AUTOSAR XML (schema 4-3-0)
standard types defined: boolean, sint16, sint8, uint16, uint8
package /AUTOSAR_AISpecification/PhysicalDimensions
  physical dimension Distance: length-exp=1  # No Dimension
  physical dimension TiNeg1: time-exp=-1  # Time -1
package /AUTOSAR_AISpecification/Units
  unit NoUnit: display-name=-, factor-si-to-unit=1, physical-dimension=Distance  # No Unit | Unit for dimensionless continuous value data types like numbers, factors and coefficients
  unit RadPerSec: display-name=rad/s, factor-si-to-unit=1, physical-dimension=TiNeg1  # Radian per Second | SI derived unit of angular velocity
package /Communication/Clusters
  can cluster CanBodyCluster: baudrate=500000, protocol-name=CAN, protocol-version=2.0B
    can physical channel CanBodyPhysicalChannel: comm-connectors=[Gateway_BodyCanConnector, BCM_BodyConnector]
      frame GeneralInfoCanFrame: id 0x5, from CentralGatewayEcu, to BodyControlEcu, frame-length=1, can-addressing-mode=EXTENDED, can-frame-rx-behavior=CAN-20, can-frame-tx-behavior=CAN-20  # CanFrame for ISignalIPdu FuelRateEngineIPdu
        pdu GeneralInfoIPdu: length=1, minimum-delay=0, transmission-mode-condition{data-filter=data-filter-type=ALWAYS, i-signal-in-i-pdu=Kl_15_ISignalToPduMapping}, transmission-mode-true-timing=cyclic-timing={time-offset=0, time-period=0.01}, unused-bit-pattern=0
          signal Kl_15ISignal: start 0, 1 bit, little-endian, init-value=0, base-type=boolean, data-constr=DC_Boolean, transfer-property=PENDING, to BodyControlEcu EngineEcu GearBoxEcu  # ISignal for SystemSignal  # Simple Status Flag
      frame DoorLeftStatusCanFrame: id 0x1, from BodyControlEcu, to CentralGatewayEcu, frame-length=2, can-addressing-mode=EXTENDED, can-frame-rx-behavior=CAN-20, can-frame-tx-behavior=CAN-20  # CanFrame for ISignalIPdu FuelRateEngineIPdu
        pdu DoorLeftStatusCanIPdu: length=2, minimum-delay=0, transmission-mode-condition{data-filter=data-filter-type=ALWAYS, i-signal-in-i-pdu=DoorLeftStatusCanIPdu/DoorClosedLeftSignal}, transmission-mode-true-timing=cyclic-timing={time-offset=0, time-period=0.01}, unused-bit-pattern=0
          signal DoorLeftClosedISignal: start 0, 1 bit, little-endian, system signal DoorClosed, init-value=0, base-type=boolean, compu-method=OpenClosed, data-constr=DC_Boolean, transfer-property=PENDING, to CentralGatewayEcu BodyControlEcu  # ISignal for SystemSignal  # Simple Status Flag
          signal DoorLeftLockedISignal: start 8, 1 bit, little-endian, system signal DoorLocked, init-value=0, base-type=boolean, compu-method=OpenClosed, data-constr=DC_Boolean, transfer-property=PENDING, to CentralGatewayEcu BodyControlEcu  # ISignal for SystemSignal  # Simple Status Flag
      frame DoorRightStatusCanFrame: id 0x2, from BodyControlEcu, to CentralGatewayEcu, frame-length=2, can-addressing-mode=EXTENDED, can-frame-rx-behavior=CAN-20, can-frame-tx-behavior=CAN-20  # CanFrame for ISignalIPdu FuelRateEngineIPdu
        pdu DoorRightStatusCanIPdu: length=2, minimum-delay=0, transmission-mode-condition{data-filter=data-filter-type=ALWAYS, i-signal-in-i-pdu=DoorRightStatusCanIPdu/DoorClosedRightSignal}, transmission-mode-true-timing=cyclic-timing={time-offset=0, time-period=0.01}, unused-bit-pattern=0
          signal DoorRightClosedISignal: start 0, 1 bit, little-endian, system signal DoorClosed, init-value=0, base-type=boolean, data-constr=DC_Boolean, transfer-property=PENDING, to CentralGatewayEcu BodyControlEcu  # ISignal for SystemSignal  # Simple Status Flag
          signal DoorRightLockedISignal: start 8, 1 bit, little-endian, system signal DoorLocked, init-value=0, base-type=boolean, compu-method=OpenClosed, data-constr=DC_Boolean, transfer-property=PENDING, to CentralGatewayEcu BodyControlEcu  # ISignal for SystemSignal  # Simple Status Flag
      frame CarLockControlCanFrame: id 0x3, from BodyControlEcu, to CentralGatewayEcu, frame-length=2, can-addressing-mode=EXTENDED, can-frame-rx-behavior=CAN-20, can-frame-tx-behavior=CAN-20  # CanFrame for ISignalIPdu FuelRateEngineIPdu
        pdu CarLockControlIPdu: length=2, minimum-delay=0, transmission-mode-condition{data-filter=data-filter-type=ALWAYS, i-signal-in-i-pdu=LockCarSignal}, transmission-mode-true-timing=cyclic-timing={time-offset=0, time-period=0.1}, unused-bit-pattern=0
          signal LockCarISignal: start 0, 1 bit, little-endian, base-type=boolean, data-constr=DC_Boolean, transfer-property=PENDING, to CentralGatewayEcu DoorEcuLeft DoorEcuRight  # ISignal for SystemSignal  # Simple Status Flag
          signal UnlockCarISignal: start 8, 1 bit, little-endian, base-type=boolean, data-constr=DC_Boolean, transfer-property=PENDING, to CentralGatewayEcu DoorEcuLeft DoorEcuRight  # ISignal for SystemSignal  # Simple Status Flag
      frame GearBoxInfoFrame: id 0x4, from CentralGatewayEcu, to BodyControlEcu, frame-length=3, can-addressing-mode=EXTENDED, can-frame-rx-behavior=CAN-20, can-frame-tx-behavior=CAN-20  # CanFrame for ISignalIPdu FuelRateEngineIPdu
        pdu GearBoxInfoIPdu: length=3, minimum-delay=0, transmission-mode-condition{data-filter=data-filter-type=ALWAYS, i-signal-in-i-pdu=CurrentGearToPduMapping}, transmission-mode-true-timing=cyclic-timing={time-offset=0, time-period=0.01}, unused-bit-pattern=0
          signal CurrentGearISignal: start 0, 8 bit, little-endian, system signal GearInfo, init-value=0, base-type=uint8, range phys -1..7, transfer-property=PENDING, to BodyControlEcu CentralGatewayEcu EngineEcu  # ISignal for SystemSignal
          signal SpeedISignal: start 8, 8 bit, little-endian, base-type=uint8, data-constr=DC_Speed, transfer-property=PENDING, to BodyControlEcu CentralGatewayEcu EngineEcu  # ISignal for SystemSignal Speed  # Engine speed before sensor failure correction
  can cluster CanPowertrainCluster: baudrate=500000, protocol-name=CAN, protocol-version=2.0B  # High speed CAN cluster for communication between ECU Controller and ECU EngineModel.
    can physical channel CanPowertrainPhysicalChannel: comm-connectors=[Engine_PowertrainCanConnector, GearBox_PowertrainCanConnector, Gateway_PowertrainCanConnector]  # High speed CAN channel.
      frame PowerStatusFrame: id 0xB, from CentralGatewayEcu, to EngineEcu GearBoxEcu, frame-length=1, can-addressing-mode=EXTENDED, can-frame-rx-behavior=CAN-20, can-frame-tx-behavior=CAN-20  # CanFrame for ISignalIPdu FuelRateEngineIPdu
        pdu PowerStatusIPdu: length=1, minimum-delay=0, transmission-mode-condition{data-filter=data-filter-type=ALWAYS, i-signal-in-i-pdu=Kl_15ISignal}, transmission-mode-true-timing=cyclic-timing={time-offset=0, time-period=0.01}, unused-bit-pattern=0
          signal Kl_15ISignal: start 0, 1 bit, little-endian, init-value=0, base-type=boolean, data-constr=DC_Boolean, transfer-property=PENDING, to BodyControlEcu EngineEcu GearBoxEcu  # ISignal for SystemSignal  # Simple Status Flag
      frame GearBoxInfoFrame: id 0xC, from GearBoxEcu, to EngineEcu CentralGatewayEcu, frame-length=3, can-addressing-mode=EXTENDED, can-frame-rx-behavior=CAN-20, can-frame-tx-behavior=CAN-20  # CanFrame for ISignalIPdu FuelRateEngineIPdu
        carries pdu GearBoxInfoIPdu: packing-byte-order=little-endian, start-position=0
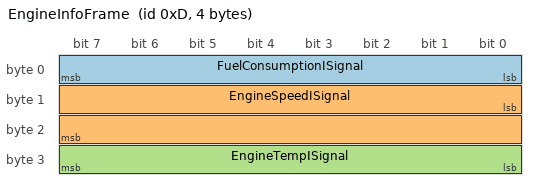
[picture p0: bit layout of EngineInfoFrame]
      frame EngineInfoFrame: id 0xD, from EngineEcu, to CentralGatewayEcu, frame-length=4, can-addressing-mode=STANDARD, can-frame-rx-behavior=CAN-20, can-frame-tx-behavior=CAN-20  # CanFrame for ISignalIPdu EngineInfoFrameIPdu
        pdu EngineInfoIPdu: length=4, minimum-delay=0, transmission-mode-condition{data-filter=data-filter-type=ALWAYS, i-signal-in-i-pdu=FuelConsumptionToPduMapping}, transmission-mode-true-timing=cyclic-timing={time-offset=0, time-period=0.1}, unused-bit-pattern=0
          signal FuelConsumptionISignal: start 0, 8 bit, little-endian, base-type=uint8, range phys 0..100 "Data constraint for current fuel consumption", transfer-property=PENDING, to CentralGatewayEcu  # ISignal for SystemSignal FuelConsumption  # Current Fuel Consumption
          signal EngineSpeedISignal: start 8, 16 bit, little-endian, base-type=sint16, range phys 0..1000 "Data constraint for current fuel consumption", implementation-data-type=uint16, transfer-property=PENDING, to CentralGatewayEcu  # ISignal for SystemSignal RoundsPerMinute  # Engine speed in rounds per minute of crankshaft
          signal EngineTempISignal: start 24, 8 bit, little-endian, base-type=sint8, range phys 0..200 "Data constraint for current fuel consumption", transfer-property=PENDING, to CentralGatewayEcu  # ISignal for SystemSignal EngineTemp  # Temperature of the engine
  lin cluster LinDoorCluster: baudrate=19200, protocol-name=LIN, protocol-version=2.1  # LIN cluster for communication between ECU BodyControllModule, ECU DoorLeft and ECU DoorRight.
    lin physical channel LinDoorPhysicalChannel: comm-connectors=[BCM_DoorConnector, LinDoorLeftConnector, LinDoorRightConnector]  # LIN physical channel.
      frame DoorLeftStatusLinFrame: id 0x1, from DoorEcuLeft, to BodyControlEcu, frame-length=2, lin-checksum=ENHANCED
        pdu DoorLeftStatusIPdu: length=2, minimum-delay=0, transmission-mode-condition{data-filter=data-filter-type=ALWAYS, i-signal-in-i-pdu=DoorLeftStatusIPdu/DoorClosedLeftSignal}, transmission-mode-true-timing=cyclic-timing={time-offset=0, time-period=0.01}, unused-bit-pattern=0
          signal DoorLeftClosedISignal: start 0, 1 bit, little-endian, system signal DoorClosed, init-value=0, base-type=boolean, compu-method=OpenClosed, data-constr=DC_Boolean, transfer-property=PENDING, to CentralGatewayEcu BodyControlEcu  # ISignal for SystemSignal  # Simple Status Flag
          signal DoorLeftLockedISignal: start 8, 1 bit, little-endian, system signal DoorLocked, init-value=0, base-type=boolean, compu-method=OpenClosed, data-constr=DC_Boolean, transfer-property=PENDING, to CentralGatewayEcu BodyControlEcu  # ISignal for SystemSignal  # Simple Status Flag
      frame DoorRightStatusLinFrame: id 0x2, from DoorEcuRight, to BodyControlEcu, frame-length=2, lin-checksum=ENHANCED
        pdu DoorRightStatusIPdu: length=2, minimum-delay=0, transmission-mode-condition{data-filter=data-filter-type=ALWAYS, i-signal-in-i-pdu=DoorRightStatusIPdu/DoorClosedRightSignal}, transmission-mode-true-timing=cyclic-timing={time-offset=0, time-period=0.01}, unused-bit-pattern=0
          signal DoorRightClosedISignal: start 0, 1 bit, little-endian, system signal DoorClosed, init-value=0, base-type=boolean, data-constr=DC_Boolean, transfer-property=PENDING, to CentralGatewayEcu BodyControlEcu  # ISignal for SystemSignal  # Simple Status Flag
          signal DoorRightLockedISignal: start 8, 1 bit, little-endian, system signal DoorLocked, init-value=0, base-type=boolean, compu-method=OpenClosed, data-constr=DC_Boolean, transfer-property=PENDING, to CentralGatewayEcu BodyControlEcu  # ISignal for SystemSignal  # Simple Status Flag
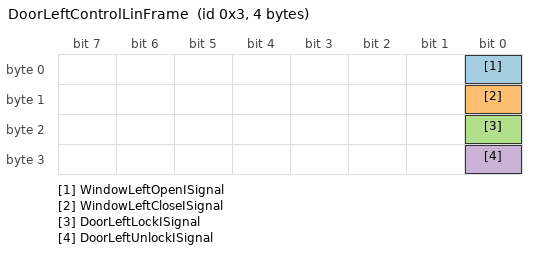
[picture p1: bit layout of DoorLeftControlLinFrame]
      frame DoorLeftControlLinFrame: id 0x3, from BodyControlEcu, to DoorEcuLeft, frame-length=4, lin-checksum=ENHANCED
        pdu DoorLeftControlIPdu: length=4, minimum-delay=0, transmission-mode-true-timing=cyclic-timing={time-offset=0, time-period=0.01}, unused-bit-pattern=0
          transmission-mode-conditions:
            data-filter=data-filter-type=ALWAYS, i-signal-in-i-pdu=CloseWindowLeftSignal
            data-filter=data-filter-type=ALWAYS, i-signal-in-i-pdu=LockDoorLeftSignal
            data-filter=data-filter-type=ALWAYS, i-signal-in-i-pdu=OpenWindowLeftSignal
            data-filter=data-filter-type=ALWAYS, i-signal-in-i-pdu=UnlockDoorLeftSignal
          signal WindowLeftOpenISignal: start 0, 1 bit, little-endian, system signal OpenWindow, base-type=boolean, data-constr=DC_Boolean, transfer-property=PENDING, to DoorEcuLeft  # ISignal for SystemSignal  # Simple Status Flag
          signal WindowLeftCloseISignal: start 8, 1 bit, little-endian, system signal CloseWindow, base-type=boolean, data-constr=DC_Boolean, transfer-property=PENDING, to DoorEcuLeft  # ISignal for SystemSignal  # Simple Status Flag
          signal DoorLeftLockISignal: start 16, 1 bit, little-endian, system signal LockDoor, base-type=boolean, transfer-property=PENDING  # ISignal for SystemSignal  # Simple Status Flag
          signal DoorLeftUnlockISignal: start 24, 1 bit, little-endian, system signal UnlockDoor, base-type=boolean, transfer-property=PENDING  # ISignal for SystemSignal  # Simple Status Flag
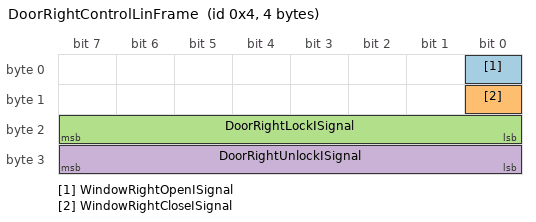
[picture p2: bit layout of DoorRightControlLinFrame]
      frame DoorRightControlLinFrame: id 0x4, from BodyControlEcu, to DoorEcuRight, frame-length=4, lin-checksum=ENHANCED
        pdu DoorRightControlIPdu: length=4, minimum-delay=0, transmission-mode-true-timing=cyclic-timing={time-offset=0, time-period=0.01}, unused-bit-pattern=0
          transmission-mode-conditions:
            data-filter=data-filter-type=ALWAYS, i-signal-in-i-pdu=DoorRightControlIPdu/CloseWindowRightSignal
            data-filter=data-filter-type=ALWAYS, i-signal-in-i-pdu=DoorRightControlIPdu/LockDoorRightSignal
            data-filter=data-filter-type=ALWAYS, i-signal-in-i-pdu=DoorRightControlIPdu/OpenWindowRightSignal
            data-filter=data-filter-type=ALWAYS, i-signal-in-i-pdu=DoorRightControlIPdu/UnlockDoorRightSignal
          signal WindowRightOpenISignal: start 0, 1 bit, little-endian, system signal OpenWindow, base-type=boolean, data-constr=DC_Boolean, transfer-property=PENDING, to DoorEcuRight  # ISignal for SystemSignal  # Simple Status Flag
          signal WindowRightCloseISignal: start 8, 1 bit, little-endian, system signal CloseWindow, base-type=boolean, data-constr=DC_Boolean, transfer-property=PENDING, to DoorEcuRight  # ISignal for SystemSignal  # Simple Status Flag
          signal DoorRightLockISignal: start 16, 8 bit, little-endian, system signal LockDoor, base-type=boolean, transfer-property=PENDING  # ISignal for SystemSignal  # Simple Status Flag
          signal DoorRightUnlockISignal: start 24, 8 bit, little-endian, system signal UnlockDoor, base-type=boolean, transfer-property=PENDING  # ISignal for SystemSignal  # Simple Status Flag
      frame CarLockControlLinFrame: id 0x5, from BodyControlEcu, to DoorEcuLeft DoorEcuRight, frame-length=2, lin-checksum=ENHANCED
        carries pdu CarLockControlIPdu: packing-byte-order=little-endian, start-position=0
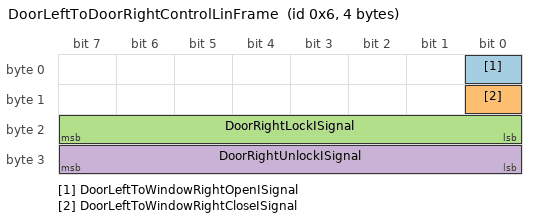
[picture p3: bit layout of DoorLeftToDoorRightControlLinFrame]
      frame DoorLeftToDoorRightControlLinFrame: id 0x6, from DoorEcuLeft, to DoorEcuRight, frame-length=4
        pdu DoorLeftToDoorRightControlIPdu: length=4, minimum-delay=0, transmission-mode-true-timing=cyclic-timing={time-offset=0, time-period=0.01}, unused-bit-pattern=0
          transmission-mode-conditions:
            data-filter=data-filter-type=ALWAYS, i-signal-in-i-pdu=DoorLeftToDoorRightControlIPdu/CloseWindowRightSignal
            data-filter=data-filter-type=ALWAYS, i-signal-in-i-pdu=DoorLeftToDoorRightControlIPdu/LockDoorRightSignal
            data-filter=data-filter-type=ALWAYS, i-signal-in-i-pdu=DoorLeftToDoorRightControlIPdu/OpenWindowRightSignal
            data-filter=data-filter-type=ALWAYS, i-signal-in-i-pdu=DoorLeftToDoorRightControlIPdu/UnlockDoorRightSignal
          signal DoorLeftToWindowRightOpenISignal: start 0, 1 bit, little-endian, system signal OpenWindow, base-type=boolean, data-constr=DC_Boolean, transfer-property=PENDING, to DoorEcuRight  # ISignal for SystemSignal  # Simple Status Flag
          signal DoorLeftToWindowRightCloseISignal: start 8, 1 bit, little-endian, system signal CloseWindow, base-type=boolean, data-constr=DC_Boolean, transfer-property=PENDING, to DoorEcuRight  # ISignal for SystemSignal  # Simple Status Flag
          signal DoorRightLockISignal: start 16, 8 bit, little-endian, system signal LockDoor, base-type=boolean, transfer-property=PENDING  # ISignal for SystemSignal  # Simple Status Flag
          signal DoorRightUnlockISignal: start 24, 8 bit, little-endian, system signal UnlockDoor, base-type=boolean, transfer-property=PENDING  # ISignal for SystemSignal  # Simple Status Flag
      lin schedule table LinDoorScheduleTable2: resume-position=START-FROM-BEGINNING, run-mode=RUN-CONTINUOUS
        table-entrys:
          delay=0.06, position-in-table=0, frame-triggering=DoorRightStatusFrameTriggering
          delay=0.06, position-in-table=1, frame-triggering=DoorLeftStatusFrameTriggering
          delay=0.06, position-in-table=2, frame-triggering=DoorLeftControlFrameTriggering
          delay=0.06, position-in-table=3, frame-triggering=DoorRightControlFrameTriggering
          delay=0.06, position-in-table=4, frame-triggering=CarLockControlFrameTriggering
          delay=0.06, position-in-table=5, frame-triggering=DoorLeftToDoorRightControlFrameTriggering
  lin cluster LinSeatCluster: baudrate=19200, protocol-name=LIN, protocol-version=2.1  # LIN cluster for communication between ECU BodyControllModule, ECU SeatLeft and ECU SeatRight.
    lin physical channel LinSeatPhysicalChannel: comm-connectors=[BCM_SeatConnector, LinSeatCommConnector, SeatRightConnector]  # LIN physical channel.
      frame SeatLeftStatusFrame: id 0x1, from SeatEcuLeft, to BodyControlEcu, frame-length=2, lin-checksum=ENHANCED
        pdu SeatLeftStatusIPdu: length=2, minimum-delay=0, transmission-mode-condition{data-filter=data-filter-type=ALWAYS, i-signal-in-i-pdu=BackrestPositionLeftSignal}, transmission-mode-true-timing=cyclic-timing={time-offset=0, time-period=0.01}, unused-bit-pattern=0
          signal BackrestPositionLeftISignal: start 0, 8 bit, little-endian, base-type=uint8, range phys 0..200, transfer-property=PENDING, to BodyControlEcu  # ISignal for SystemSignal
          signal SeatingPositionLeftISignal: start 8, 8 bit, little-endian, base-type=uint8, range phys 0..200, transfer-property=PENDING, to BodyControlEcu  # ISignal for SystemSignal
      frame SeatLeftControlFrame: id 0x2, from BodyControlEcu, to SeatEcuLeft, frame-length=2, lin-checksum=ENHANCED
        pdu SeatLeftControlIPdu: length=2, minimum-delay=0, transmission-mode-true-timing=cyclic-timing={time-offset=0, time-period=0.01}, unused-bit-pattern=0
          transmission-mode-conditions:
            data-filter=data-filter-type=ALWAYS, i-signal-in-i-pdu=BackrestMotorLeftSignal
            data-filter=data-filter-type=ALWAYS, i-signal-in-i-pdu=SeatingMotorLeftSignal
          signal BackrestMotorLeftISignal: start 0, 8 bit, little-endian, base-type=uint8, transfer-property=PENDING, to SeatEcuLeft  # ISignal for SystemSignal
          signal SeatingMotorLeftISignal: start 8, 8 bit, little-endian, base-type=uint8, transfer-property=PENDING, to SeatEcuLeft  # ISignal for SystemSignal
      frame SeatRightStatusFrame: id 0x3, from SeatEcuRight, to BodyControlEcu, frame-length=2, lin-checksum=ENHANCED
        pdu SeatRightStatusIPdu: length=2, minimum-delay=0, transmission-mode-true-timing=cyclic-timing={time-offset=0, time-period=0.01}, unused-bit-pattern=0
          transmission-mode-conditions:
            data-filter=data-filter-type=ALWAYS, i-signal-in-i-pdu=BackrestPositionRightSignal
            data-filter=data-filter-type=ALWAYS, i-signal-in-i-pdu=SeatingPositionRightSignal
          signal BackrestPositionRightISignal: start 0, 8 bit, little-endian, base-type=uint8, range phys 0..200, transfer-property=PENDING, to BodyControlEcu  # ISignal for SystemSignal
          signal SeatingPositionRightISignal: start 8, 8 bit, little-endian, base-type=uint8, range phys 0..200, transfer-property=PENDING, to BodyControlEcu  # ISignal for SystemSignal
      frame SeatRightControlFrame: id 0x4, from BodyControlEcu, to SeatEcuRight, frame-length=2, lin-checksum=ENHANCED
        pdu SeatRightControlIPdu: length=2, minimum-delay=0, transmission-mode-true-timing=cyclic-timing={time-offset=0, time-period=0.01}, unused-bit-pattern=0
          transmission-mode-conditions:
            data-filter=data-filter-type=ALWAYS, i-signal-in-i-pdu=BackrestMotorRightSignal
            data-filter=data-filter-type=ALWAYS, i-signal-in-i-pdu=SeatingMotorRightSignal
          signal BackrestMotorRightISignal: start 0, 8 bit, little-endian, base-type=uint8, transfer-property=PENDING, to SeatEcuRight  # ISignal for SystemSignal
          signal SeatingMotorRightISignal: start 8, 8 bit, little-endian, base-type=uint8, transfer-property=PENDING, to SeatEcuRight  # ISignal for SystemSignal
      lin schedule table LinSeatScheduleTable1: resume-position=START-FROM-BEGINNING, run-mode=RUN-CONTINUOUS
        table-entrys:
          delay=0.08, position-in-table=1, frame-triggering=SeatLeftStatusFrameTriggering
          delay=0.08, position-in-table=2, frame-triggering=SeatLeftControlFrameTriggering
          delay=0.08, position-in-table=3, frame-triggering=SeatRightStatusFrameTriggering
          delay=0.08, position-in-table=4, frame-triggering=SeatRightControlFrameTriggering
      lin schedule table LinSeatScheduleTable2: resume-position=START-FROM-BEGINNING, run-mode=RUN-CONTINUOUS
        table-entrys:
          delay=0.08, position-in-table=0, frame-triggering=SeatRightStatusFrameTriggering
          delay=0.08, position-in-table=3, frame-triggering=SeatLeftStatusFrameTriggering
          delay=0.08, position-in-table=2, frame-triggering=SeatRightControlFrameTriggering
          delay=0.08, position-in-table=1, frame-triggering=SeatLeftControlFrameTriggering
package /Communication/ISignalIPdus
  pdu CrashInfoCanIPdu: length=3, minimum-delay=0, transmission-mode-condition{data-filter=data-filter-type=ALWAYS, i-signal-in-i-pdu=AirbagISignalToPduMapping}, transmission-mode-true-timing=cyclic-timing={time-offset=0, time-period=0.01}, unused-bit-pattern=0
    signal AirbagISignal: start 0, 8 bit, little-endian, system signal AirbagInfo, base-type=uint8, transfer-property=PENDING  # ISignal for SystemSignal
    signal AccelerationISignal: start 8, 16 bit, little-endian, base-type=sint16, transfer-property=PENDING  # ISignal for SystemSignal Acceleration  # Acceleration value of vehicle
  pdu CrashInfoDoorLinIPdu: length=3, minimum-delay=0, transmission-mode-true-timing=cyclic-timing={time-offset=0, time-period=0.01}, unused-bit-pattern=0
    transmission-mode-conditions:
      data-filter=data-filter-type=ALWAYS, i-signal-in-i-pdu=AirbagSignalToPduMapping
      data-filter=data-filter-type=ALWAYS, i-signal-in-i-pdu=CrashInfoDoorLinIPdu/AccelerationSignalToPduMapping
    signal AirbagISignal: start 0, 8 bit, little-endian, system signal AirbagInfo, base-type=uint8, transfer-property=PENDING  # ISignal for SystemSignal
    signal AccelerationISignal: start 8, 16 bit, little-endian, base-type=sint16, transfer-property=PENDING  # ISignal for SystemSignal Acceleration  # Acceleration value of vehicle
package /Communication/ISignals
  i signal CorrectedSpeedISignal: length=16, base-type=sint16, system-signal=CorrectedSpeed  # ISignal for SystemSignal CorrectedSpeed
package /Communication/SystemSignals
  4 x system signal:
    ControlSignal
    CorrectedSpeed  # Engine speed before sensor failure correction
    PositionInformation
    SimpleStatusFlag  # Simple Status Flag
package /Compositions/ControllerComposition
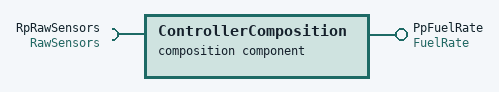
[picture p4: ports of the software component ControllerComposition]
  composition sw component type ControllerComposition  # Describes the software architecture of the fault tolerant fuel rate controller.
    require port RpRawSensors: required-interface=RawSensors  # Raw (uncorrected) sensor signals.
    provide port PpFuelRate: provided-interface=FuelRate  # The fuel injection rate for the engine.
    4 x component:
      FuelsysSensors: type=FuelsysSensors
      FuelsysController: type=FuelsysController
      FuelsysCombi: type=FuelsysCombi
      FuelsysParameters: type=FuelsysParameters
    connect FuelsysSensors.PpCorrectedSensors -> FuelsysController.RpCorrectedSensors
    connect FuelsysSensors.PpFuelMode -> FuelsysController.RpFuelMode
    connect FuelsysParameters.PpAxisParams -> FuelsysSensors.RpAxisParams
    connect FuelsysParameters.PpAxisParams -> FuelsysController.RpAxisParams
    delegate FuelsysSensors.RpRawSensors <-> outer port ControllerComposition/RpRawSensors
    delegate FuelsysController.PpFuelRate <-> outer port ControllerComposition/PpFuelRate
package /Compositions/EngineModelComposition
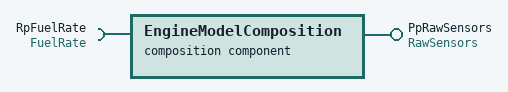
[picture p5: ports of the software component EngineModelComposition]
  composition sw component type EngineModelComposition  # Describes the software architecture of the engine model, i.e. the environment of the fault tolerant fuel rate controller.
    require port RpFuelRate: required-interface=FuelRate  # The fuel injection rate for the engine.
    provide port PpRawSensors: provided-interface=RawSensors  # Raw (uncorrected) sensor signals.
    component EngineModel: type=EngineModel
    delegate EngineModel.RpFuelRate <-> outer port EngineModelComposition/RpFuelRate
    delegate EngineModel.PpRawSensors <-> outer port EngineModelComposition/PpRawSensors
package /Compositions/RootSwComposition
  composition sw component type RootSwComposition  # Root software composition. Describes a fault tolerant fuel injection system in closed loop with an engine model (plant).
    component ControllerComposition: type=ControllerComposition
    component EngineModelComposition: type=EngineModelComposition
    connect ControllerComposition.PpFuelRate -> EngineModelComposition.RpFuelRate
    connect EngineModelComposition.PpRawSensors -> ControllerComposition.RpRawSensors
package /Ecus/Door
  ecu instance DoorEcuLeft: com-configuration-gw-time-base=0.01, com-configuration-rx-time-base=0.01, com-configuration-tx-time-base=0.01, diagnostic-address=1, sleep-mode-supported=false, wake-up-over-bus-supported=false  # DoorLeft ECU.
    lin slave LinDoorLeftCommController: protocol-version=2.0  # LIN slave communication controller.
    lin communication connector LinDoorLeftConnector: comm-controller=LinDoorLeftCommController  # Connector for LIN bus.
  ecu instance DoorEcuRight: com-configuration-gw-time-base=0.01, com-configuration-rx-time-base=0.01, com-configuration-tx-time-base=0.01, diagnostic-address=2, sleep-mode-supported=false, wake-up-over-bus-supported=false  # DoorRight ECU.
    lin slave LinDoorRightCommController: protocol-version=2.0  # LIN slave communication controller.
    lin communication connector LinDoorRightConnector: comm-controller=LinDoorRightCommController  # Connector for LIN bus.
package /Ecus/Gateways
  ecu instance BodyControlEcu: com-configuration-gw-time-base=0.01, com-configuration-rx-time-base=0.01, com-configuration-tx-time-base=0.01, com-enable-mdt-for-cyclic-transmission=true, diagnostic-address=3, sleep-mode-supported=false, wake-up-over-bus-supported=false  # BodyControlModule ECU.
    lin master LinSeatCommController: protocol-version=2.0, time-base=0.01  # LIN master communication controller.
    can communication controller CanBodyCommController  # Bus controller for high speed CAN bus for communication of engine signals.
    lin master LinDoorCommController: protocol-version=2.0, time-base=0.01
    lin communication connector BCM_SeatConnector: comm-controller=LinSeatCommController  # Connector for LIN bus.
    can communication connector BCM_BodyConnector: comm-controller=BodyControlEcu/CanBodyCommController  # Connector for high speed CAN bus for communication of engine signals.
    lin communication connector BCM_DoorConnector: comm-controller=LinDoorCommController
  ecu instance CentralGatewayEcu: com-configuration-gw-time-base=0.01, com-configuration-rx-time-base=0.01, com-configuration-tx-time-base=0.01, diagnostic-address=4, sleep-mode-supported=false, wake-up-over-bus-supported=false  # Central Gateway ECU.
    lin master LinBodyCommController: protocol-version=2.0, time-base=0.01  # LIN master communication controller.
    can communication controller CanBodyCommController  # Bus controller for high speed CAN bus for communication of engine signals.
    can communication controller CanPowertrainController
    can communication connector Gateway_BodyCanConnector: comm-controller=CentralGatewayEcu/CanBodyCommController  # Connector for high speed CAN bus for communication of engine signals.
    can communication connector Gateway_PowertrainCanConnector: comm-controller=CanPowertrainController
package /Ecus/PowertrainCan
  ecu instance EngineEcu: com-configuration-gw-time-base=0.01, com-configuration-rx-time-base=0.01, com-configuration-tx-time-base=0.01, diagnostic-address=5, sleep-mode-supported=false, wake-up-over-bus-supported=false  # EngineController ECU.
    can communication controller CanEngineCommController  # Bus controller for high speed CAN bus for communication of engine signals.
    can communication connector Engine_PowertrainCanConnector: comm-controller=CanEngineCommController  # Connector for high speed CAN bus for communication of engine signals.
  ecu instance GearBoxEcu: com-configuration-gw-time-base=0.01, com-configuration-rx-time-base=0.01, com-configuration-tx-time-base=0.01, diagnostic-address=6, sleep-mode-supported=false, wake-up-over-bus-supported=false  # GearBoxController ECU.
    can communication controller CanGearBoxCommController  # Bus controller for high speed CAN bus for communication of engine signals.
    can communication connector GearBox_PowertrainCanConnector: comm-controller=CanGearBoxCommController  # Connector for high speed CAN bus for communication of engine signals.
package /Ecus/Seat
  ecu instance SeatEcuLeft: com-configuration-gw-time-base=0.01, com-configuration-rx-time-base=0.01, com-configuration-tx-time-base=0.01, diagnostic-address=7, sleep-mode-supported=false, wake-up-over-bus-supported=false  # SeatLeft ECU.
    lin slave LinSeatLeftCommController: protocol-version=2.0  # LIN slave communication controller.
    lin communication connector LinSeatCommConnector: comm-controller=LinSeatLeftCommController  # Connector for LIN bus.
  ecu instance SeatEcuRight: com-configuration-gw-time-base=0.01, com-configuration-rx-time-base=0.01, com-configuration-tx-time-base=0.01, diagnostic-address=8, sleep-mode-supported=false, wake-up-over-bus-supported=false  # SeatRight ECU.
    lin slave LinSeatCommController: protocol-version=2.0  # LIN slave communication controller.
    lin communication connector SeatRightConnector: comm-controller=LinSeatCommController  # Connector for LIN bus.
package /SharedElements/ApplicationDataTypes
  app type Airbag: category=VALUE, base-type=uint8, range phys 0..255  # Airbag Information
  app type Boolean: category=BOOLEAN, compu {0=FALSE, 1=TRUE}  # Boolean.
  application record data type CombiSensorsStruct: category=STRUCTURE  # ApplicationDataType for signals used by the Combi instrument.
    4 x application record element, all with category=VALUE:
      Throttle: type=Throttle  # Throttle plate angle.
      Speed: type=Speed  # Engine angular velocity.
      Ego: type=Ego  # Exhaust gas oxygene (EGO).
      Map: type=Map  # Manifold absolute pressure (MAP).
  app type ControlSignal: category=VALUE, base-type=uint8, range phys 0..2  # Control signal for motor steering
  range DC_Boolean: phys 0..1  # Data constraint for boolean values.
  range DC_Ego: phys 0..2  # Data constraint for exhaust gas oxygene (EGO).
  range DC_Speed: phys 0..255  # Data constraint for engine angular velocity.
  4 x app type, all with category=VALUE:
    Ego: compu {phys=raw/16384} "Linear compu method for exhaust gas oxygene (EGO)."  # ApplicationDataType for exhaust gas oxygene (EGO).
    FuelRate: compu {phys=raw/4096} "Linear compu method for fuel injection rate.", range phys 0..7.9 "Data constraint for fuel injection rate."  # ApplicationDataType for fuel injection rate.
    Gear: base-type=uint8, range phys -1..7  # Gear Information
    Map: compu {phys=raw/32768} "Linear compu method for manifold absolute pressure (MAP).", range phys 0..1 "Data constraint for manifold absolute pressure (MAP)."  # ApplicationDataType for manifold absolute pressure (MAP).
  application array data type MapAxis: category=ARRAY  # ApplicationDataType for MapAxis
    element MapAxis_ELEMENT: category=VALUE, type=Map, array-size-semantics=FIXED-SIZE, max-number-of-elements=19  # Element of MapAxis
  app type OpenClosed: category=VALUE, compu-method=OpenClosed
  app type Position: category=VALUE, base-type=uint8, range phys 0..200, unit=cm
  application record data type SensorsStruct: category=STRUCTURE  # ApplicationDataType for sensor data after failure correction.
    4 x application record element, all with category=VALUE:
      Throttle: type=Throttle  # Throttle plate angle.
      Speed: type=Speed  # Engine angular velocity.
      Ego: type=Ego  # Exhaust gas oxygene (EGO).
      Map: type=Map  # Manifold absolute pressure (MAP).
  app type Speed: category=VALUE, base-type=uint16, compu {phys=raw*0.25; unit rad/s} "Linear compu method for engine angular velocity.", data-constr=DC_Speed
  application array data type SpeedAxis: category=ARRAY  # ApplicationDataType for SpeedAxis
    element SpeedAxis_ELEMENT: category=VALUE, type=Speed, array-size-semantics=FIXED-SIZE, max-number-of-elements=18  # Element of SpeedAxis
  app type Throttle: category=VALUE, compu {phys=raw/512; unit Grad} "Linear compu method for throttle plate angle.", range phys 0..108 "Data constraint for throttle plate angle."  # ApplicationDataType for throttle plate angle.
  application array data type ThrottleAxis: category=ARRAY  # ApplicationDataType for ThrottleAxis
    element ThrottleAxis_ELEMENT: category=VALUE, type=Throttle, array-size-semantics=FIXED-SIZE, max-number-of-elements=17  # Element of ThrottleAxis
package /SharedElements/CompuMethods
  compu method OpenClosed: 1=closed, 0=open  # Indicate states (0 - open, 1 - closed)
package /SharedElements/Constants
  6 x constant specification, all with category=ARRAY:
    IV_AxisParams_MapAxis: value-spec=[0.05, 0.1, 0.15, 0.2, 0.25, 0.3, 0.35, 0.4, 0.45, 0.5, 0.55, 0.6, 0.65, 0.7, 0.75, 0.8, 0.85, 0.9, 0.95]  # Application constant for calibration parameter MapAxis
    IV_AxisParams_MapAxis_IDT: value-spec=[1638, 3277, 4915, 6554, 8192, 9830, 11469, 13107, 14746, 16384, 18022, 19661, 21299, 22938, 24576, 26214, 27853, 29491, 31130]  # Application constant for calibration parameter MapAxis
    IV_AxisParams_SpeedAxis: value-spec=[50, 75, 100, 125, 150, 175, 200, 250, 300, 350, 400, 450, 500, 600, 700, 800, 900, 1000]  # Application constant for calibration parameter MapAxis
    IV_AxisParams_SpeedAxis_IDT: value-spec=[200, 300, 400, 500, 600, 700, 800, 1000, 1200, 1400, 1600, 1800, 2000, 2400, 2800, 3200, 3600, 4000]  # Application constant for calibration parameter MapAxis
    IV_AxisParams_ThrottleAxis: value-spec=[0, 3, 6, 9, 12, 15, 18, 21, 24, 27, 30, 35, 46, 57, 68, 79, 90]  # Application constant for calibration parameter ThrottleAxis
    IV_AxisParams_ThrottleAxis_IDT: value-spec=[0, 1536, 3072, 4608, 6144, 7680, 9216, 10752, 12288, 13824, 15360, 17920, 23552, 29184, 34816, 40448, 46080]  # Application constant for calibration parameter ThrottleAxis
package /SharedElements/ImplementationDataTypes
  5 x impl type:
    CombiSensorsStruct_IDT: category=STRUCTURE  # ImplementationDataType for ApplicationDataType CombiSensorsStruct
      4 x element, all with category=TYPE_REFERENCE, implementation-data-type=uint16:
        Throttle  # Element implementation for ApplicationRecordDataType CombiSensorsStruct
        Speed  # Element implementation for ApplicationRecordDataType CombiSensorsStruct
        Ego  # Element implementation for ApplicationRecordDataType CombiSensorsStruct
        Map  # Element implementation for ApplicationRecordDataType CombiSensorsStruct
    MapAxis_IDT: category=ARRAY  # ImplementationDataType for ApplicationDataType MapAxis
      element MapAxis_ELEMENT: array-size=19, array-size-semantics=FIXED-SIZE, implementation-data-type=uint16  # Element implementation type for ApplicationArrayDataType MapAxis
    SensorsStruct_IDT: category=STRUCTURE  # ImplementationDataType for ApplicationDataType SensorsStruct
      4 x element, all with category=TYPE_REFERENCE, implementation-data-type=uint16:
        Throttle  # Element implementation for ApplicationRecordDataType SensorsStruct
        Speed  # Element implementation for ApplicationRecordDataType SensorsStruct
        Ego  # Element implementation for ApplicationRecordDataType SensorsStruct
        Map  # Element implementation for ApplicationRecordDataType SensorsStruct
    SpeedAxis_IDT: category=ARRAY  # ImplementationDataType for ApplicationDataType SpeedAxis
      element SpeedAxis_ELEMENT: array-size=18, array-size-semantics=FIXED-SIZE, implementation-data-type=uint16  # Element implementation type for ApplicationArrayDataType SpeedAxis
    ThrottleAxis_IDT: category=ARRAY  # ImplementationDataType for ApplicationDataType ThrottleAxis
      element ThrottleAxis_ELEMENT: array-size=17, array-size-semantics=FIXED-SIZE, implementation-data-type=uint16  # Element implementation type for ApplicationArrayDataType ThrottleAxis
package /SharedElements/Interfaces
  parameter interface AxisParams  # Calibration parameters for the fuel rate controller.
    parameter data prototype ThrottleAxis: category=VAL_BLK, sw-addr-method=SwAddrM_CalPrm, sw-calibration-access=READ-WRITE, sw-impl-policy=CONST, type=ThrottleAxis  # Base points of throttle axis.
    parameter data prototype SpeedAxis: category=VAL_BLK, sw-addr-method=SwAddrM_CalPrm, sw-calibration-access=READ-WRITE, sw-impl-policy=CONST, type=SpeedAxis  # Base points of speed axis.
    parameter data prototype MapAxis: category=VAL_BLK, sw-addr-method=SwAddrM_CalPrm, sw-calibration-access=READ-WRITE, sw-impl-policy=CONST, type=MapAxis  # Base points of MAP axis.
  sender receiver interface CombiSensors  # SenderReceiverInterface for sensor signals used by the Combi instrument.
    data Position: sw-calibration-access=READ-ONLY, type=Position
  mode switch interface FuelMode  # ModeSwitchInterface. Determines the fuel injection mode.
    mode group FuelMode: sw-calibration-access=READ-ONLY, type=FuelMode  # The fuel injection mode, dependent on the engine state and the sensor failures.
  sender receiver interface FuelRate  # SenderReceiverInterface for fuel injection rate.
    data FuelRate: sw-calibration-access=READ-ONLY, type=FuelRate  # Fuel injection rate.
  sender receiver interface RawSensors  # SenderReceiverInterface for raw (uncorrected) sensor signals from the engine model.
    4 x data, all with sw-calibration-access=READ-ONLY:
      Throttle: type=Throttle  # Throttle plate angle.
      Speed: type=Speed  # Engine angular velocity.
      Ego: type=Ego  # Exhaust gas oxygene (EGO).
      Map: type=Map  # Manifold absolute pressure (MAP).
  sender receiver interface Sensors  # SenderReceiverInterface for sensor data after failure correction.
    data Sensors: sw-calibration-access=READ-ONLY, type=SensorsStruct  # Struct with sensor data after failure correction.
package /SharedElements/ModeDeclarationGroups
  mode declaration group FuelMode: category=EXPLICIT_ORDER, initial-mode=LowWarmup, on-transition-value=0  # The fuel injection mode, dependent on the engine state and the sensor failures.
    4 x mode:
      Disabled: value=1  # Constant represents zero fuel mode.
      LowNormal: value=2  # Constant represents 'low emissions' or stoichiometric fuel mixture mode when the O2 sensor is in normal mode.
      LowWarmup: value=3  # Constant represents 'low emissions' or stoichiometric fuel mixture mode when the O2 sensor is in warmup mode.
      Rich: value=4  # Constant represents rich fuel mixture mode.
package /SharedElements/SwAddrMethods
  sw addr method SwAddrM_CalPrm: memory-allocation-keyword-policy=ADDR-METHOD-SHORT-NAME, section-type=CALPRM  # SwAddrMethod for calibration parameters.
package /SharedElements/Units
  unit Cm: display-name=cm, factor-si-to-unit=100, offset-si-to-unit=0, physical-dimension=Distance  # Distance in cm
  unit Grad: display-name=Grad, factor-si-to-unit=1, offset-si-to-unit=0, physical-dimension=Distance  # Unit for angles [360 Grad = 2 pi rad].
package /Swcs/EngineModel
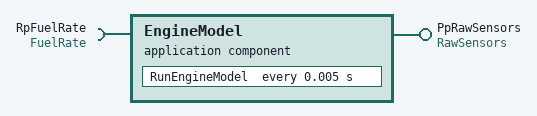
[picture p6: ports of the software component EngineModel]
  application sw component type EngineModel  # Simple engine model. Simulates engine speed for given fuel rate.
    require port RpFuelRate: nonqueued-receiver-com-spec{data-element=FuelRate, init-value=constant-reference=IV_RpFuelRate_FuelRate}, required-interface=FuelRate  # The fuel injection rate for the engine.
    provide port PpRawSensors: provided-interface=RawSensors  # Raw (uncorrected) sensor signals.
      provided-com-specs:
        data-element=Throttle, init-value=constant-reference=IV_PpRawSensors_Throttle
        data-element=Speed, init-value=constant-reference=IV_PpRawSensors_Speed
        data-element=Ego, init-value=constant-reference=IV_PpRawSensors_Ego
        data-element=Map, init-value=constant-reference=IV_PpRawSensors_Map
    behavior EngineModelBehavior: constant-value-mapping=EngineModel_ConstantSpecificationMappingSet, data-type-mapping=EngineModel_DataTypeMappingSet, handle-termination-and-restart=NO-SUPPORT  # Internal behavior for SWC EngineModel.
      timing event EngineModel5ms: start-on-event=RunEngineModel, period=0.005  # Triggers the EngineModel runnable every 5 ms.
      runnable RunEngineModel  # Computes the behavior of the engine model.
        data-read-access:
          access DRA_RpFuelRate_FuelRate: accessed-variable=RpFuelRate.FuelRate
        data-write-access:
          4 x access:
            DWA_PpRawSensors_Throttle: accessed-variable=PpRawSensors.Throttle
            DWA_PpRawSensors_Speed: accessed-variable=PpRawSensors.Speed
            DWA_PpRawSensors_Ego: accessed-variable=PpRawSensors.Ego
            DWA_PpRawSensors_Map: accessed-variable=PpRawSensors.Map
  swc implementation EngineModelImplementation: programming-language=C, sw-version=1.0.0, used-code-generator=HandCode, vendor-id=35, behavior=EngineModelBehavior
    code-descriptors:
      code SourceCode: artifact-descriptors=[{short-label=EngineModel.c, category=SWSRC}, {short-label=EngineModel.h, category=SWHDR}]
    resource consumption ResourceConsumption
  constant specification mapping set EngineModel_ConstantSpecificationMappingSet  # ConstantSpecificationMappingSet for EngineModelBehavior
    mappings:
      appl-constant=IV_RpFuelRate_FuelRate, impl-constant=IV_RpFuelRate_FuelRate_IDT
      appl-constant=IV_PpRawSensors_Throttle, impl-constant=IV_PpRawSensors_Throttle_IDT
      appl-constant=IV_PpRawSensors_Speed, impl-constant=IV_PpRawSensors_Speed_IDT
      appl-constant=IV_PpRawSensors_Ego, impl-constant=IV_PpRawSensors_Ego_IDT
      appl-constant=IV_PpRawSensors_Map, impl-constant=IV_PpRawSensors_Map_IDT
  data type mapping set EngineModel_DataTypeMappingSet  # DataTypeMappingSet for EngineModelBehavior
    data-type-maps:
      application-data-type=Throttle, implementation-data-type=uint16
      application-data-type=Speed, implementation-data-type=uint16
      application-data-type=Ego, implementation-data-type=uint16
      application-data-type=Map, implementation-data-type=uint16
      application-data-type=FuelRate, implementation-data-type=uint16
package /Swcs/EngineModel/Constants
  10 x constant specification, all with category=VALUE, value-spec=0:
    IV_PpRawSensors_Ego  # Initvalue constant for data element Ego
    IV_PpRawSensors_Ego_IDT  # Initvalue constant for data element Ego
    IV_PpRawSensors_Map  # Initvalue constant for data element Map
    IV_PpRawSensors_Map_IDT  # Initvalue constant for data element Map
    IV_PpRawSensors_Speed  # Initvalue constant for data element Speed
    IV_PpRawSensors_Speed_IDT  # Initvalue constant for data element Speed
    IV_PpRawSensors_Throttle  # Initvalue constant for data element Throttle
    IV_PpRawSensors_Throttle_IDT  # Initvalue constant for data element Throttle
    IV_RpFuelRate_FuelRate  # Initvalue constant for data element FuelRate
    IV_RpFuelRate_FuelRate_IDT  # Initvalue constant for data element FuelRate
package /Swcs/FuelsysController
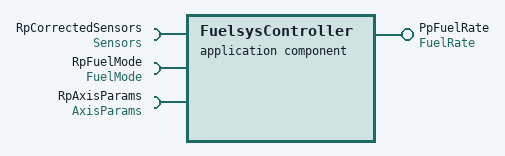
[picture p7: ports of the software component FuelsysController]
  application sw component type FuelsysController  # Controller component. Computes the fuel injection rate.
    require port RpCorrectedSensors: nonqueued-receiver-com-spec{data-element=Sensors, init-value=constant-reference=IV_RpCorrectedSensors_Sensors}, required-interface=Sensors  # Sensor signals after failure correction.
    require port RpFuelMode: required-interface=FuelMode  # Defines the fuel injection mode.
    require port RpAxisParams: required-interface=AxisParams  # Calibration parameters for the lookup table axes.
      required-com-specs:
        init-value=constant-reference=IV_AxisParams_ThrottleAxis, parameter=ThrottleAxis
        init-value=constant-reference=IV_AxisParams_SpeedAxis, parameter=SpeedAxis
        init-value=constant-reference=IV_AxisParams_MapAxis, parameter=MapAxis
    provide port PpFuelRate: nonqueued-sender-com-spec{data-element=FuelRate, init-value=constant-reference=IV_PpFuelRate_FuelRate}, provided-interface=FuelRate  # The fuel injection rate for the engine.
    behavior FuelsysControllerBehavior: constant-value-mapping=FuelsysController_ConstantSpecificationMappingSet, data-type-mapping=FuelsysController_DataTypeMappingSet, handle-termination-and-restart=NO-SUPPORT  # Internal behavior for SWC FuelsysController.
      4 x timing event, all with period=0.01:
        AirflowCalculation10ms: start-on-event=AirflowCalculation  # Triggers the AirflowCalculation runnable every 10 ms.
        AirflowCorrection10ms: disabled-mode=[RpFuelMode.FuelMode.LowWarmup, RpFuelMode.FuelMode.Rich, RpFuelMode.FuelMode.Disabled], start-on-event=AirflowCorrection  # Triggers the AirflowCorrection runnable every 10 ms.
        FuelRateCalcNormal10ms: disabled-mode=[RpFuelMode.FuelMode.LowWarmup, RpFuelMode.FuelMode.Rich, RpFuelMode.FuelMode.Disabled], start-on-event=FuelRateCalcNormal  # Triggers the FuelRateCalcNormal runnable every 10 ms.
        FuelRateCalcRich10ms: disabled-mode=[RpFuelMode.FuelMode.LowNormal, RpFuelMode.FuelMode.Disabled], start-on-event=FuelRateCalcRich  # Triggers the FuelRateCalcRich runnable every 10 ms.
      swc mode switch event OnEntryDisableMode: start-on-event=OnEntryDisable, activation=ON-ENTRY, mode=RpFuelMode.FuelMode.Disabled  # This event is invoked when the fuel mode enters the DISABLE state.
      implicit-inter-runnable-variables:
        data IrvAirflowCorrection: category=VALUE, sw-calibration-access=READ-ONLY, display-format=%5.3f, type=IrvAirflowCorrection, init-value=constant-reference=IV_IrvAirflowCorrection  # Airflow feedback correction.
        data IrvEstimatedAirflow: category=VALUE, sw-calibration-access=READ-ONLY, display-format=%6.3f, type=IrvEstimatedAirflow, init-value=constant-reference=IV_IrvEstimatedAirflow  # Estimated airflow.
      5 x runnable:
        AirflowCalculation  # Intake airflow estimation.
          data-read-access:
            access DRA_RpCorrectedSensors_Sensors: accessed-variable=RpCorrectedSensors.Sensors
          parameter access CPA_RpAxisParams_SpeedAxis: accessed-parameter=RpAxisParams.SpeedAxis
          parameter access CPA_RpAxisParams_MapAxis: accessed-parameter=RpAxisParams.MapAxis
          written-local-variables:
            access IRVWA_IrvEstimatedAirflow: accessed-variable=IrvEstimatedAirflow
        AirflowCorrection  # Intake airflow closed-loop correction.
          data-read-access:
            access DRA_RpCorrectedSensors_Sensors: accessed-variable=RpCorrectedSensors.Sensors
          written-local-variables:
            access IRVWA_IrvAirflowCorrection: accessed-variable=IrvAirflowCorrection
        FuelRateCalcNormal  # Performs fuel rate calculation for normal low mixture.
          data-write-access:
            access DWA_PpFuelRate_FuelRate: accessed-variable=PpFuelRate.FuelRate
          parameter access SCPVA_FaNormal: accessed-parameter=FaNormal
          read-local-variables:
            access IRVRA_IrvEstimatedAirflow: accessed-variable=IrvEstimatedAirflow
            access IRVRA_IrvAirflowCorrection: accessed-variable=IrvAirflowCorrection
        FuelRateCalcRich  # Performs fuel rate calculation for rich low mixture.
          data-write-access:
            access DWA_PpFuelRate_FuelRate: accessed-variable=PpFuelRate.FuelRate
          parameter access SCPVA_FaRich: accessed-parameter=FaRich
          read-local-variables:
            access IRVRA_IrvEstimatedAirflow: accessed-variable=IrvEstimatedAirflow
            access IRVRA_IrvAirflowCorrection: accessed-variable=IrvAirflowCorrection
        OnEntryDisable  # This runnable is executed when the fuel mode enters the DISABLE state.
      shared-parameters:
        parameter data prototype FaNormal: category=VALUE, sw-addr-method=SwAddrM_CalPrm, sw-calibration-access=READ-WRITE, display-format=%6.3f, type=FaRatio, init-value=constant-reference=IV_FaNormal  # FuelRate/Airflow for normal fuel injection mode [default = 1/14.6].
        parameter data prototype FaRich: category=VALUE, sw-addr-method=SwAddrM_CalPrm, sw-calibration-access=READ-WRITE, display-format=%5.3f, type=FaRatio, init-value=constant-reference=IV_FaRich  # FuelRate/Airflow for normal fuel injection mode [default = 1/(14.6*0.8)].
  swc implementation FuelsysControllerImplementation: programming-language=C, sw-version=1.0.0, used-code-generator=TargetLink, vendor-id=35, behavior=FuelsysControllerBehavior
    code-descriptors:
      code SourceCode
        artifact-descriptors:
          short-label=FuelsysController.c, category=SWSRC
          short-label=FuelsysController.h, category=SWHDR
          short-label=tl_defines_Ctrl.h, category=SWHDR
          short-label=Tab2DIntpI1T1.c, category=SWSRC
          short-label=Tab2DIntpI1T1.h, category=SWHDR
          short-label=Tab2DS17I2T4169.c, category=SWSRC
          short-label=Tab2DS17I2T4169.h, category=SWHDR
          short-label=TabIdxS17T1.c, category=SWSRC
          short-label=TabIdxS17T1.h, category=SWHDR
    required-artifacts:
      dependency on artifact dsfxp_h_Library: artifact-descriptor={short-label=dsfxp.h, category=SWHDR}, usages=CODEGENERATION  # TargetLink fixed point library. Contains utility functions and macros for code generated by TargetLink.If this library is really needed depends on the code patterns used in the TargetLink model.
    resource consumption ResourceConsumption
      memory section CODE  # Global or static functions (ROM)
      memory section CONST_16: alignment=16, symbol=CONST  # Global or static constants (ROM, aligned to 16 bit)
      memory section CALIB_16: alignment=16, sw-addrmethod=SwAddrM_CalPrm, symbol=CALIB  # Global or static calibration parameters (Flash, aligned to 16 bit)
  constant specification mapping set FuelsysController_ConstantSpecificationMappingSet  # ConstantSpecificationMappingSet for FuelsysControllerBehavior
    mappings:
      appl-constant=IV_RpCorrectedSensors_Sensors, impl-constant=IV_RpCorrectedSensors_Sensors_IDT
      appl-constant=IV_PpFuelRate_FuelRate, impl-constant=IV_PpFuelRate_FuelRate_IDT
      appl-constant=IV_IrvAirflowCorrection, impl-constant=IV_IrvAirflowCorrection_IDT
      appl-constant=IV_IrvEstimatedAirflow, impl-constant=IV_IrvEstimatedAirflow_IDT
      appl-constant=IV_FaNormal, impl-constant=IV_FaNormal_IDT
      appl-constant=IV_FaRich, impl-constant=IV_FaRich_IDT
      appl-constant=IV_AxisParams_ThrottleAxis, impl-constant=IV_AxisParams_ThrottleAxis_IDT
      appl-constant=IV_AxisParams_SpeedAxis, impl-constant=IV_AxisParams_SpeedAxis_IDT
      appl-constant=IV_AxisParams_MapAxis, impl-constant=IV_AxisParams_MapAxis_IDT
  data type mapping set FuelsysController_DataTypeMappingSet: mode-request-type-map{implementation-data-type=uint8, mode-group=FuelMode}  # DataTypeMappingSet for FuelsysControllerBehavior
    data-type-maps:
      application-data-type=SensorsStruct, implementation-data-type=SensorsStruct_IDT
      application-data-type=FuelRate, implementation-data-type=uint16
      application-data-type=ThrottleAxis, implementation-data-type=ThrottleAxis_IDT
      application-data-type=SpeedAxis, implementation-data-type=SpeedAxis_IDT
      application-data-type=MapAxis, implementation-data-type=MapAxis_IDT
      application-data-type=IrvAirflowCorrection, implementation-data-type=sint16
      application-data-type=IrvEstimatedAirflow, implementation-data-type=uint16
      application-data-type=FaRatio, implementation-data-type=uint16
package /Swcs/FuelsysController/ApplicationDataTypes
  app type FaRatio: category=VALUE, compu {phys=raw/262144} "CompuMethod for FaRatio", range phys 0.05..0.15  # ApplicationDataType for FaNormal
  app type IrvAirflowCorrection: category=VALUE, compu {phys=raw/16384} "CompuMethod for IrvAirflowCorrection"  # ApplicationDataType for IrvAirflowCorrection
  app type IrvEstimatedAirflow: category=VALUE, compu {phys=raw/1024} "CompuMethod for IrvEstimatedAirflow"  # ApplicationDataType for IrvEstimatedAirflow
package /Swcs/FuelsysController/Constants
  12 x constant specification:
    IV_FaNormal: category=VALUE, value-spec=0.0684931506849315  # FuelRate/Airflow for normal fuel injection mode [default = 1/14.6].
    IV_FaNormal_IDT: category=VALUE, value-spec=17955  # FuelRate/Airflow for normal fuel injection mode [default = 1/14.6].
    IV_FaRich: category=VALUE, value-spec=0.0856164383561644  # FuelRate/Airflow for normal fuel injection mode [default = 1/(14.6*0.8)].
    IV_FaRich_IDT: category=VALUE, value-spec=22444  # FuelRate/Airflow for normal fuel injection mode [default = 1/(14.6*0.8)].
    IV_IrvAirflowCorrection: category=VALUE, value-spec=0  # Airflow feedback correction.
    IV_IrvAirflowCorrection_IDT: category=VALUE, value-spec=0  # Airflow feedback correction.
    IV_IrvEstimatedAirflow: category=VALUE, value-spec=0  # Estimated airflow.
    IV_IrvEstimatedAirflow_IDT: category=VALUE, value-spec=0  # Estimated airflow.
    IV_PpFuelRate_FuelRate: category=VALUE, value-spec=0  # Initvalue constant for data element FuelRate
    IV_PpFuelRate_FuelRate_IDT: category=VALUE, value-spec=0  # Initvalue constant for data element FuelRate
    IV_RpCorrectedSensors_Sensors: category=STRUCTURE, value-spec=fields=[0, 0, 0, 0]  # Initvalue constant for data element Sensors
    IV_RpCorrectedSensors_Sensors_IDT: category=STRUCTURE, value-spec=fields=[0, 0, 0, 0]  # Initvalue constant for data element Sensors
package /Swcs/FuelsysParameters
  parameter sw component type FuelsysParameters: constant-mapping=FuelsysParameters_ConstantSpecificationMappingSet, data-type-mapping=FuelsysParameters_DataTypeMappingSet  # Provides the calibration parameters for the fuelsys controller.
    provide port PpAxisParams: provided-interface=AxisParams  # Calibration parameters for the lookup table axes.
      provided-com-specs:
        init-value=constant-reference=IV_AxisParams_ThrottleAxis, parameter=ThrottleAxis
        init-value=constant-reference=IV_AxisParams_SpeedAxis, parameter=SpeedAxis
        init-value=constant-reference=IV_AxisParams_MapAxis, parameter=MapAxis
  constant specification mapping set FuelsysParameters_ConstantSpecificationMappingSet  # ConstantSpecificationMappingSet for FuelsysParameters
    mappings:
      appl-constant=IV_AxisParams_ThrottleAxis, impl-constant=IV_AxisParams_ThrottleAxis_IDT
      appl-constant=IV_AxisParams_SpeedAxis, impl-constant=IV_AxisParams_SpeedAxis_IDT
      appl-constant=IV_AxisParams_MapAxis, impl-constant=IV_AxisParams_MapAxis_IDT
  data type mapping set FuelsysParameters_DataTypeMappingSet  # DataTypeMappingSet for FuelsysParameters
    data-type-maps:
      application-data-type=ThrottleAxis, implementation-data-type=ThrottleAxis_IDT
      application-data-type=SpeedAxis, implementation-data-type=SpeedAxis_IDT
      application-data-type=MapAxis, implementation-data-type=MapAxis_IDT
package /Swcs/FuelsysSensors
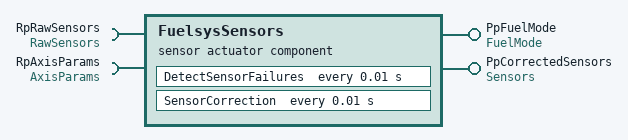
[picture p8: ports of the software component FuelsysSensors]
  sensor actuator sw component type FuelsysSensors  # Sensor component. Detects sensor failures and corrects measurements, if a sensor fails
    require port RpRawSensors: required-interface=RawSensors  # Raw (uncorrected) sensor signals.
      required-com-specs:
        data-element=Throttle, init-value=constant-reference=IV_RpRawSensors_Throttle
        data-element=Speed, init-value=constant-reference=IV_RpRawSensors_Speed
        data-element=Ego, init-value=constant-reference=IV_RpRawSensors_Ego
        data-element=Map, init-value=constant-reference=IV_RpRawSensors_Map
    require port RpAxisParams: required-interface=AxisParams  # Calibration parameters for the lookup table axes.
      required-com-specs:
        init-value=constant-reference=IV_AxisParams_ThrottleAxis, parameter=ThrottleAxis
        init-value=constant-reference=IV_AxisParams_SpeedAxis, parameter=SpeedAxis
        init-value=constant-reference=IV_AxisParams_MapAxis, parameter=MapAxis
    provide port PpFuelMode: mode-switch-sender-com-spec{mode-group=FuelMode, queue-length=1}, provided-interface=FuelMode  # Defines the fuel injection mode.
    provide port PpCorrectedSensors: nonqueued-sender-com-spec{data-element=Sensors, init-value=constant-reference=IV_PpCorrectedSensors_Sensors}, provided-interface=Sensors  # Sensor signals after failure correction.
    behavior FuelsysSensorsBehavior: constant-value-mapping=FuelsysSensors_ConstantSpecificationMappingSet, data-type-mapping=FuelsysSensors_DataTypeMappingSet, handle-termination-and-restart=NO-SUPPORT  # Internal behavior for SWC FuelsysSensors.
      timing event DetectSensorFailures10ms: start-on-event=DetectSensorFailures, period=0.01  # Triggers the DetectSensorFailures runnable every 10 ms.
      timing event SensorCorrection10ms: start-on-event=SensorCorrection, period=0.01  # Triggers the SensorCorrection runnable every 10 ms.
      implicit-inter-runnable-variables:
        4 x data, all with category=BOOLEAN, type=Boolean:
          IrvFailThrottle: init-value=constant-reference=IV_IrvFailThrottle  # Failure of throttle angle sensor.
          IrvFailSpeed: init-value=constant-reference=IV_IrvFailSpeed  # Failure of engine speed sensor.
          IrvFailEgo: init-value=constant-reference=IV_IrvFailEgo  # Failure of oxygene sensor.
          IrvFailMap: init-value=constant-reference=IV_IrvFailMap  # Failure of manifold absolute pressure (MAP) sensor.
      runnable DetectSensorFailures  # Detects sensor failures and determines the fuel injection mode.
        data-read-access:
          4 x access:
            DRA_RpRawSensors_Throttle: accessed-variable=RpRawSensors.Throttle
            DRA_RpRawSensors_Speed: accessed-variable=RpRawSensors.Speed
            DRA_RpRawSensors_Ego: accessed-variable=RpRawSensors.Ego
            DRA_RpRawSensors_Map: accessed-variable=RpRawSensors.Map
        mode switch point MSP_PpFuelMode_FuelMode: mode-group=PpFuelMode.FuelMode
        written-local-variables:
          4 x access:
            IRVWA_IrvFailThrottle: accessed-variable=IrvFailThrottle
            IRVWA_IrvFailSpeed: accessed-variable=IrvFailSpeed
            IRVWA_IrvFailEgo: accessed-variable=IrvFailEgo
            IRVWA_IrvFailMap: accessed-variable=IrvFailMap
      runnable SensorCorrection  # Performs sensor correction and manages fault redundancy.
        data-read-access:
          4 x access:
            DRA_RpRawSensors_Throttle: accessed-variable=RpRawSensors.Throttle
            DRA_RpRawSensors_Speed: accessed-variable=RpRawSensors.Speed
            DRA_RpRawSensors_Ego: accessed-variable=RpRawSensors.Ego
            DRA_RpRawSensors_Map: accessed-variable=RpRawSensors.Map
        data-write-access:
          access DWA_PpCorrectedSensors_Sensors: accessed-variable=PpCorrectedSensors.Sensors
        parameter access CPA_RpAxisParams_ThrottleAxis: accessed-parameter=RpAxisParams.ThrottleAxis
        parameter access CPA_RpAxisParams_SpeedAxis: accessed-parameter=RpAxisParams.SpeedAxis
        parameter access CPA_RpAxisParams_MapAxis: accessed-parameter=RpAxisParams.MapAxis
        read-local-variables:
          4 x access:
            IRVRA_IrvFailThrottle: accessed-variable=IrvFailThrottle
            IRVRA_IrvFailSpeed: accessed-variable=IrvFailSpeed
            IRVRA_IrvFailEgo: accessed-variable=IrvFailEgo
            IRVRA_IrvFailMap: accessed-variable=IrvFailMap
  swc implementation FuelsysSensorsImplementation: programming-language=C, sw-version=1.0.0, used-code-generator=TargetLink, vendor-id=35, behavior=FuelsysSensorsBehavior
    code-descriptors:
      code SourceCode
        artifact-descriptors:
          short-label=FuelsysSensors.c, category=SWSRC
          short-label=FuelsysSensors.h, category=SWHDR
          short-label=tl_defines_Sns.h, category=SWHDR
          short-label=Tab2DIntpI1T1.c, category=SWSRC
          short-label=Tab2DIntpI1T1.h, category=SWHDR
          short-label=TabIdxS17T1.c, category=SWSRC
          short-label=TabIdxS17T1.h, category=SWHDR
    required-artifacts:
      dependency on artifact dsfxp_h_Library: artifact-descriptor={short-label=dsfxp.h, category=SWHDR}, usages=CODEGENERATION  # TargetLink fixed point library. Contains utility functions and macros for code generated by TargetLink.If this library is really needed depends on the code patterns used in the TargetLink model.
    resource consumption ResourceConsumption
      memory section CODE  # Global or static functions (ROM)
      memory section CONST_16: alignment=16, symbol=CONST  # Global or static constants (ROM, aligned to 16 bit)
  constant specification mapping set FuelsysSensors_ConstantSpecificationMappingSet  # ConstantSpecificationMappingSet for FuelsysSensorsBehavior
    mappings:
      appl-constant=IV_RpRawSensors_Throttle, impl-constant=IV_RpRawSensors_Throttle_IDT
      appl-constant=IV_RpRawSensors_Speed, impl-constant=IV_RpRawSensors_Speed_IDT
      appl-constant=IV_RpRawSensors_Ego, impl-constant=IV_RpRawSensors_Ego_IDT
      appl-constant=IV_RpRawSensors_Map, impl-constant=IV_RpRawSensors_Map_IDT
      appl-constant=IV_PpCorrectedSensors_Sensors, impl-constant=IV_PpCorrectedSensors_Sensors_IDT
      appl-constant=IV_IrvFailThrottle, impl-constant=IV_IrvFailThrottle_IDT
      appl-constant=IV_IrvFailSpeed, impl-constant=IV_IrvFailSpeed_IDT
      appl-constant=IV_IrvFailEgo, impl-constant=IV_IrvFailEgo_IDT
      appl-constant=IV_IrvFailMap, impl-constant=IV_IrvFailMap_IDT
      appl-constant=IV_AxisParams_ThrottleAxis, impl-constant=IV_AxisParams_ThrottleAxis_IDT
      appl-constant=IV_AxisParams_SpeedAxis, impl-constant=IV_AxisParams_SpeedAxis_IDT
      appl-constant=IV_AxisParams_MapAxis, impl-constant=IV_AxisParams_MapAxis_IDT
  data type mapping set FuelsysSensors_DataTypeMappingSet: mode-request-type-map{implementation-data-type=uint8, mode-group=FuelMode}  # DataTypeMappingSet for FuelsysSensorsBehavior
    data-type-maps:
      Boolean
      application-data-type=Throttle, implementation-data-type=uint16
      application-data-type=Speed, implementation-data-type=uint16
      application-data-type=Ego, implementation-data-type=uint16
      application-data-type=Map, implementation-data-type=uint16
      application-data-type=SensorsStruct, implementation-data-type=SensorsStruct_IDT
      application-data-type=ThrottleAxis, implementation-data-type=ThrottleAxis_IDT
      application-data-type=SpeedAxis, implementation-data-type=SpeedAxis_IDT
      application-data-type=MapAxis, implementation-data-type=MapAxis_IDT
package /Swcs/FuelsysSensors/Constants
  18 x constant specification:
    IV_IrvFailEgo: category=BOOLEAN, value-spec=0  # Failure of oxygene sensor.
    IV_IrvFailEgo_IDT: category=BOOLEAN, value-spec=0  # Failure of oxygene sensor.
    IV_IrvFailMap: category=BOOLEAN, value-spec=0  # Failure of manifold absolute pressure (MAP) sensor.
    IV_IrvFailMap_IDT: category=BOOLEAN, value-spec=0  # Failure of manifold absolute pressure (MAP) sensor.
    IV_IrvFailSpeed: category=BOOLEAN, value-spec=0  # Failure of engine speed sensor.
    IV_IrvFailSpeed_IDT: category=BOOLEAN, value-spec=0  # Failure of engine speed sensor.
    IV_IrvFailThrottle: category=BOOLEAN, value-spec=0  # Failure of throttle angle sensor.
    IV_IrvFailThrottle_IDT: category=BOOLEAN, value-spec=0  # Failure of throttle angle sensor.
    IV_PpCorrectedSensors_Sensors: category=STRUCTURE, value-spec=fields=[0, 0, 0, 0]  # Initvalue constant for data element Sensors
    IV_PpCorrectedSensors_Sensors_IDT: category=STRUCTURE, value-spec=fields=[0, 0, 0, 0]  # Initvalue constant for data element Sensors
    IV_RpRawSensors_Ego: category=VALUE, value-spec=0  # Initvalue constant for data element Ego
    IV_RpRawSensors_Ego_IDT: category=VALUE, value-spec=0  # Initvalue constant for data element Ego
    IV_RpRawSensors_Map: category=VALUE, value-spec=0  # Initvalue constant for data element Map
    IV_RpRawSensors_Map_IDT: category=VALUE, value-spec=0  # Initvalue constant for data element Map
    IV_RpRawSensors_Speed: category=VALUE, value-spec=0 rad/s  # Initvalue constant for data element Speed
    IV_RpRawSensors_Speed_IDT: category=VALUE, value-spec=0  # Initvalue constant for data element Speed
    IV_RpRawSensors_Throttle: category=VALUE, value-spec=0 Grad  # Initvalue constant for data element Throttle
    IV_RpRawSensors_Throttle_IDT: category=VALUE, value-spec=0  # Initvalue constant for data element Throttle
package /Swcs/SeatLeft
  application sw component type FuelsysCombi  # Combi instrument. Displays the engine speed and the average fuel consumption.
    behavior FuelsysCombiBehavior: constant-value-mapping=FuelsysCombi_ConstantSpecificationMappingSet, data-type-mapping=FuelsysCombi_DataTypeMappingSet, handle-termination-and-restart=NO-SUPPORT  # Internal behavior for SWC FuelsysCombi.
      timing event FuelsysCombi100ms: start-on-event=RunFuelsysCombi, period=0.1  # Triggers the FuelsysCombi runnable every 100 ms.
      runnable RunFuelsysCombi  # Displays data on the Combi instrument.
  swc implementation FuelsysCombiImplementation: programming-language=C, sw-version=1.0.0, used-code-generator=HandCode, vendor-id=35, behavior=FuelsysCombiBehavior
    code-descriptors:
      code SourceCode: artifact-descriptors=[{short-label=FuelsysCombi.c, category=SWSRC}, {short-label=FuelsysCombi.h, category=SWHDR}]
    resource consumption ResourceConsumption
  constant specification mapping set FuelsysCombi_ConstantSpecificationMappingSet: mappings=[IV_RpCombiSensors_Sensors]  # ConstantSpecificationMappingSet for FuelsysCombiBehavior
  data type mapping set FuelsysCombi_DataTypeMappingSet  # DataTypeMappingSet for FuelsysCombiBehavior
    data-type-maps:
      application-data-type=CombiSensorsStruct, implementation-data-type=CombiSensorsStruct_IDT
      application-data-type=FuelRate, implementation-data-type=uint16
package /Swcs/SeatLeft/Constants
  constant specification IV_RpCombiSensors_Sensors: category=STRUCTURE, value-spec=fields=[0, 0, 0, 0]  # Initvalue constant for data element Sensors
package /Systems/AR_Demo_Lin_Can
  system AR_Demo_Lin_Can: category=SYSTEM_EXTRACT, system-version=1.0.0  # AUTOSAR System. Describes a fault tolerant fuel injection system.
    system mapping Mapping
      data-mappings:
        sender-receiver-to-signal-mapping=ControllerComposition.FuelsysController.RootSoftwareComposition.PpFuelRate.FuelRate
        sender-receiver-to-signal-group-mapping={data-element=ControllerComposition.FuelsysSensors.RootSoftwareComposition.PpCorrectedSensors.Sensors, type-mapping=sender-rec-record-type-mapping=record-element-mappings=[SensorsStruct/Throttle, {application-record-element=SensorsStruct/Speed, system-signal=CorrectedSpeed}, SensorsStruct/Ego, SensorsStruct/Map]}
        sender-receiver-to-signal-mapping=EngineModelComposition.EngineModel.RootSoftwareComposition.PpRawSensors.Throttle
        sender-receiver-to-signal-mapping={data-element=EngineModelComposition.EngineModel.RootSoftwareComposition.PpRawSensors.Speed, system-signal=RawSpeed}
        sender-receiver-to-signal-mapping=EngineModelComposition.EngineModel.RootSoftwareComposition.PpRawSensors.Ego
        sender-receiver-to-signal-mapping=EngineModelComposition.EngineModel.RootSoftwareComposition.PpRawSensors.Map
      sw-impl-mappings:
        4 x swc to impl mapping:
          SwImplMapping: component-implementation=FuelsysSensorsImplementation, component=RootSoftwareComposition.ControllerComposition.FuelsysSensors
          SwImplMapping1: component-implementation=FuelsysControllerImplementation, component=RootSoftwareComposition.ControllerComposition.FuelsysController
          SwImplMapping2: component-implementation=EngineModelImplementation, component=RootSoftwareComposition.EngineModelComposition.EngineModel
          SwImplMapping3: component-implementation=FuelsysCombiImplementation, component=RootSoftwareComposition.ControllerComposition.FuelsysCombi
      sw-mappings:
        swc to ecu mapping SwMapping: ecu-instance=BodyControlEcu
          component:
            RootSoftwareComposition.ControllerComposition.FuelsysSensors
            RootSoftwareComposition.ControllerComposition.FuelsysController
            RootSoftwareComposition.ControllerComposition.FuelsysParameters
        swc to ecu mapping SwMapping1: component=RootSoftwareComposition.EngineModelComposition.EngineModel, ecu-instance=EngineEcu
        swc to ecu mapping SwMapping2: component=RootSoftwareComposition.ControllerComposition.FuelsysCombi, ecu-instance=SeatEcuLeft
    root-software-compositions:
      root sw composition prototype RootSoftwareComposition: software-composition=RootSwComposition
